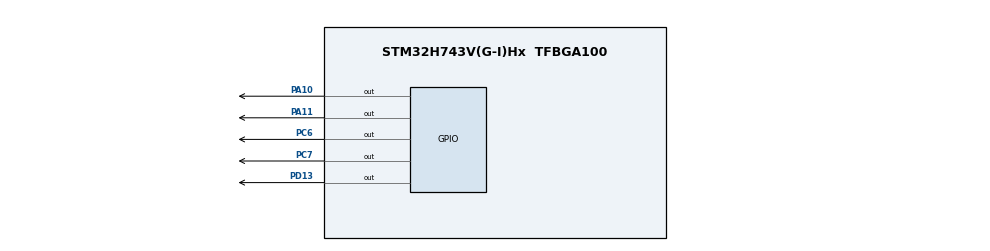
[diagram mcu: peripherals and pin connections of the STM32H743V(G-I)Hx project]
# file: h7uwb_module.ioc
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CORTEX_M7.default_mode_Activation=1
FREERTOS.Tasks01=defaultTask,24,128,StartDefaultTask,Default,NULL,Dynamic,NULL,NULL
FREERTOS.configUSE_NEWLIB_REENTRANT=1
Mcu.Family=STM32H7
Mcu.Name=STM32H743V(G-I)Hx
Mcu.Package=TFBGA100
NVIC.PriorityGroup=NVIC_PRIORITYGROUP_4
NVIC.TIM1_UP_IRQn=true\:15\:0\:false\:false\:true\:false\:false\:true\:true
NVIC.TimeBase=TIM1_UP_IRQn
NVIC.TimeBaseIP=TIM1
PA10.Signal=GPIO_Output
PA11.Signal=GPIO_Output
PC6.Signal=GPIO_Output
PC7.Signal=GPIO_Output
PD13.Signal=GPIO_Output
PH0-OSC_IN\ (PH0).Mode=HSE-External-Oscillator
PH0-OSC_IN\ (PH0).Signal=RCC_OSC_IN
PH1-OSC_OUT\ (PH1).Mode=HSE-External-Oscillator
PH1-OSC_OUT\ (PH1).Signal=RCC_OSC_OUT
ProjectManager.HeapSize=0x200
ProjectManager.StackSize=0x400
ProjectManager.TargetToolchain=STM32CubeIDE
RCC.ADCFreq_Value=129000000
RCC.APB1Freq_Value=120000000
RCC.APB2Freq_Value=120000000
RCC.APB3Freq_Value=120000000
RCC.APB4Freq_Value=120000000
RCC.CortexFreq_Value=120000000
RCC.DIVM1=4
RCC.DIVN1=15
RCC.HCLKFreq_Value=120000000
RCC.HSE_VALUE=8000000
RCC.PLL2FRACN=0
RCC.PLL3FRACN=0
RCC.PLLFRACN=0
RCC.SYSCLKFreq_VALUE=120000000
RCC.SYSCLKSource=RCC_SYSCLKSOURCE_PLLCLK
RCC.USBFreq_Value=120000000
VP_FREERTOS_VS_CMSIS_V2.Mode=CMSIS_V2
VP_MEMORYMAP_VS_MEMORYMAP.Mode=CurAppReg
VP_SYS_VS_tim1.Mode=TIM1
board=custom

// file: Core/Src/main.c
/* USER CODE BEGIN Header */
/**
  ******************************************************************************
  * @file           : main.c
  * @brief          : Main program body
  ******************************************************************************
  * @attention
  *
  * Copyright (c) 2025 STMicroelectronics.
  * All rights reserved.
  *
  * This software is licensed under terms that can be found in the LICENSE file
  * in the root directory of this software component.
  * If no LICENSE file comes with this software, it is provided AS-IS.
  *
  ******************************************************************************
  */
/* USER CODE END Header */
#include "main.h"
#include "cmsis_os.h"
#include "memorymap.h"
#include "gpio.h"

void SystemClock_Config(void);
static void MPU_Config(void);
void MX_FREERTOS_Init(void);

int main(void)
{

  /* MPU Configuration--------------------------------------------------------*/
  MPU_Config();

  /* MCU Configuration--------------------------------------------------------*/

  /* Reset of all peripherals, Initializes the Flash interface and the Systick. */
  HAL_Init();

  /* Configure the system clock */
  SystemClock_Config();

  /* Initialize all configured peripherals */
  MX_GPIO_Init();

  /* Init scheduler */
  osKernelInitialize();

  /* Call init function for freertos objects (in cmsis_os2.c) */
  MX_FREERTOS_Init();

  /* Start scheduler */
  osKernelStart();

  /* We should never get here as control is now taken by the scheduler */

  /* Infinite loop */
  while (1)
  {

  }
}

void SystemClock_Config(void)
{
  LL_FLASH_SetLatency(LL_FLASH_LATENCY_2);
  while(LL_FLASH_GetLatency()!= LL_FLASH_LATENCY_2)
  {
  }
  LL_PWR_ConfigSupply(LL_PWR_LDO_SUPPLY);
  LL_PWR_SetRegulVoltageScaling(LL_PWR_REGU_VOLTAGE_SCALE3);
  while (LL_PWR_IsActiveFlag_VOS() == 0)
  {
  }
  LL_RCC_HSI_Enable();

   /* Wait till HSI is ready */
  while(LL_RCC_HSI_IsReady() != 1)
  {

  }
  LL_RCC_HSI_SetCalibTrimming(64);
  LL_RCC_HSI_SetDivider(LL_RCC_HSI_DIV1);
  LL_RCC_PLL_SetSource(LL_RCC_PLLSOURCE_HSI);
  LL_RCC_PLL1P_Enable();
  LL_RCC_PLL1_SetVCOInputRange(LL_RCC_PLLINPUTRANGE_8_16);
  LL_RCC_PLL1_SetVCOOutputRange(LL_RCC_PLLVCORANGE_WIDE);
  LL_RCC_PLL1_SetM(4);
  LL_RCC_PLL1_SetN(15);
  LL_RCC_PLL1_SetP(2);
  LL_RCC_PLL1_SetQ(2);
  LL_RCC_PLL1_SetR(2);
  LL_RCC_PLL1_Enable();

   /* Wait till PLL is ready */
  while(LL_RCC_PLL1_IsReady() != 1)
  {
  }

   /* Intermediate AHB prescaler 2 when target frequency clock is higher than 80 MHz */
   LL_RCC_SetAHBPrescaler(LL_RCC_AHB_DIV_2);

  LL_RCC_SetSysClkSource(LL_RCC_SYS_CLKSOURCE_PLL1);

   /* Wait till System clock is ready */
  while(LL_RCC_GetSysClkSource() != LL_RCC_SYS_CLKSOURCE_STATUS_PLL1)
  {

  }
  LL_RCC_SetSysPrescaler(LL_RCC_SYSCLK_DIV_1);
  LL_RCC_SetAHBPrescaler(LL_RCC_AHB_DIV_1);
  LL_RCC_SetAPB1Prescaler(LL_RCC_APB1_DIV_1);
  LL_RCC_SetAPB2Prescaler(LL_RCC_APB2_DIV_1);
  LL_RCC_SetAPB3Prescaler(LL_RCC_APB3_DIV_1);
  LL_RCC_SetAPB4Prescaler(LL_RCC_APB4_DIV_1);
  LL_SetSystemCoreClock(120000000);

   /* Update the time base */
  if (HAL_InitTick (TICK_INT_PRIORITY) != HAL_OK)
  {
    Error_Handler();
  }
}

 /* MPU Configuration */

void MPU_Config(void)
{

  /* Disables the MPU */
  LL_MPU_Disable();

  /** Initializes and configures the Region and the memory to be protected
  */
  LL_MPU_ConfigRegion(LL_MPU_REGION_NUMBER0, 0x87, 0x0, LL_MPU_REGION_SIZE_4GB|LL_MPU_TEX_LEVEL0|LL_MPU_REGION_NO_ACCESS|LL_MPU_INSTRUCTION_ACCESS_DISABLE|LL_MPU_ACCESS_SHAREABLE|LL_MPU_ACCESS_NOT_CACHEABLE|LL_MPU_ACCESS_NOT_BUFFERABLE);
  /* Enables the MPU */
  LL_MPU_Enable(LL_MPU_CTRL_PRIVILEGED_DEFAULT);

}

void HAL_TIM_PeriodElapsedCallback(TIM_HandleTypeDef *htim)
{
  if (htim->Instance == TIM1) {
    HAL_IncTick();
  }
}

void Error_Handler(void)
{
  __disable_irq();
  while (1)
  {
  }
}

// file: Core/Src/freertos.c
/* USER CODE BEGIN Header */
/**
  ******************************************************************************
  * File Name          : freertos.c
  * Description        : Code for freertos applications
  ******************************************************************************
  * @attention
  *
  * Copyright (c) 2025 STMicroelectronics.
  * All rights reserved.
  *
  * This software is licensed under terms that can be found in the LICENSE file
  * in the root directory of this software component.
  * If no LICENSE file comes with this software, it is provided AS-IS.
  *
  ******************************************************************************
  */
/* USER CODE END Header */

#include "FreeRTOS.h"
#include "task.h"
#include "main.h"
#include "cmsis_os.h"

/* Definitions for defaultTask */
osThreadId_t defaultTaskHandle;
const osThreadAttr_t defaultTask_attributes = {
  .name = "defaultTask",
  .stack_size = 128 * 4,
  .priority = (osPriority_t) osPriorityNormal,
};

void StartDefaultTask(void *argument);

void MX_FREERTOS_Init(void); /* (MISRA C 2004 rule 8.1) */

void MX_FREERTOS_Init(void) {

  /* Create the thread(s) */
  /* creation of defaultTask */
  defaultTaskHandle = osThreadNew(StartDefaultTask, NULL, &defaultTask_attributes);

}

void StartDefaultTask(void *argument)
{
  /* USER CODE BEGIN StartDefaultTask */
  /* Infinite loop */
  for(;;)
  {
	  // LED2
	  LL_GPIO_TogglePin(GPIOA,LL_GPIO_PIN_11);
	  osDelay(1000);
  }
  /* USER CODE END StartDefaultTask */
}
